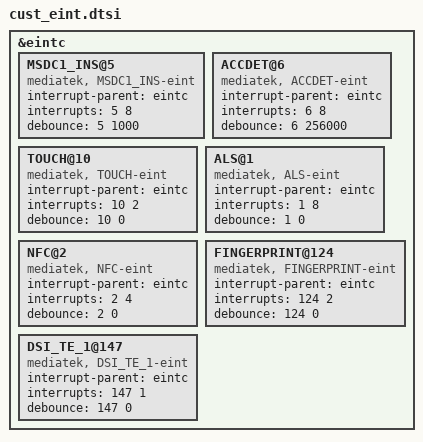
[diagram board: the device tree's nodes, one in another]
/*
 * Generated by MTK SP DrvGen Version 03.13.6 for MT6753. Copyright MediaTek Inc. (C) 2013.
 * Sun Sep 11 02:21:42 2016
 * Do Not Modify the File.
 *
 * M1612 note: this generated-layer file is NOT included in the DTS build
 * (only cust.dtsi is, via mt6753.dtsi). Kept in sync with the M1612 live DT
 * dump: ACCDET EINT9->EINT6, ALS EINT18->EINT1 (INFERENCE, pin GPIO1),
 * ACCEL_GYRO_INT1/2 and SWTP removed, NFC EINT144->EINT2, FINGERPRINT
 * EINT124 added (bus/fingerprint@ interrupts = <124 2>).
 */

/*************************
 * EINT DTSI File
*************************/

&eintc {
	MSDC1_INS@5 {
		compatible = "mediatek, MSDC1_INS-eint";
		interrupt-parent = <&eintc>;
		interrupts = <5 8>;
		debounce = <5 1000>;
	};

	ACCDET@6 {
		compatible = "mediatek, ACCDET-eint";
		interrupt-parent = <&eintc>;
		interrupts = <6 8>;
		debounce = <6 256000>;
	};

	TOUCH@10 {
		compatible = "mediatek, TOUCH-eint";
		interrupt-parent = <&eintc>;
		interrupts = <10 2>;
		debounce = <10 0>;
	};

	ALS@1 {
		compatible = "mediatek, ALS-eint";
		interrupt-parent = <&eintc>;
		interrupts = <1 8>;
		debounce = <1 0>;
	};

	NFC@2 {
		compatible = "mediatek, NFC-eint";
		interrupt-parent = <&eintc>;
		interrupts = <2 4>;
		debounce = <2 0>;
	};

	FINGERPRINT@124 {
		compatible = "mediatek, FINGERPRINT-eint";
		interrupt-parent = <&eintc>;
		interrupts = <124 2>;
		debounce = <124 0>;
	};

	DSI_TE_1@147 {
		compatible = "mediatek, DSI_TE_1-eint";
		interrupt-parent = <&eintc>;
		interrupts = <147 1>;
		debounce = <147 0>;
	};

};
